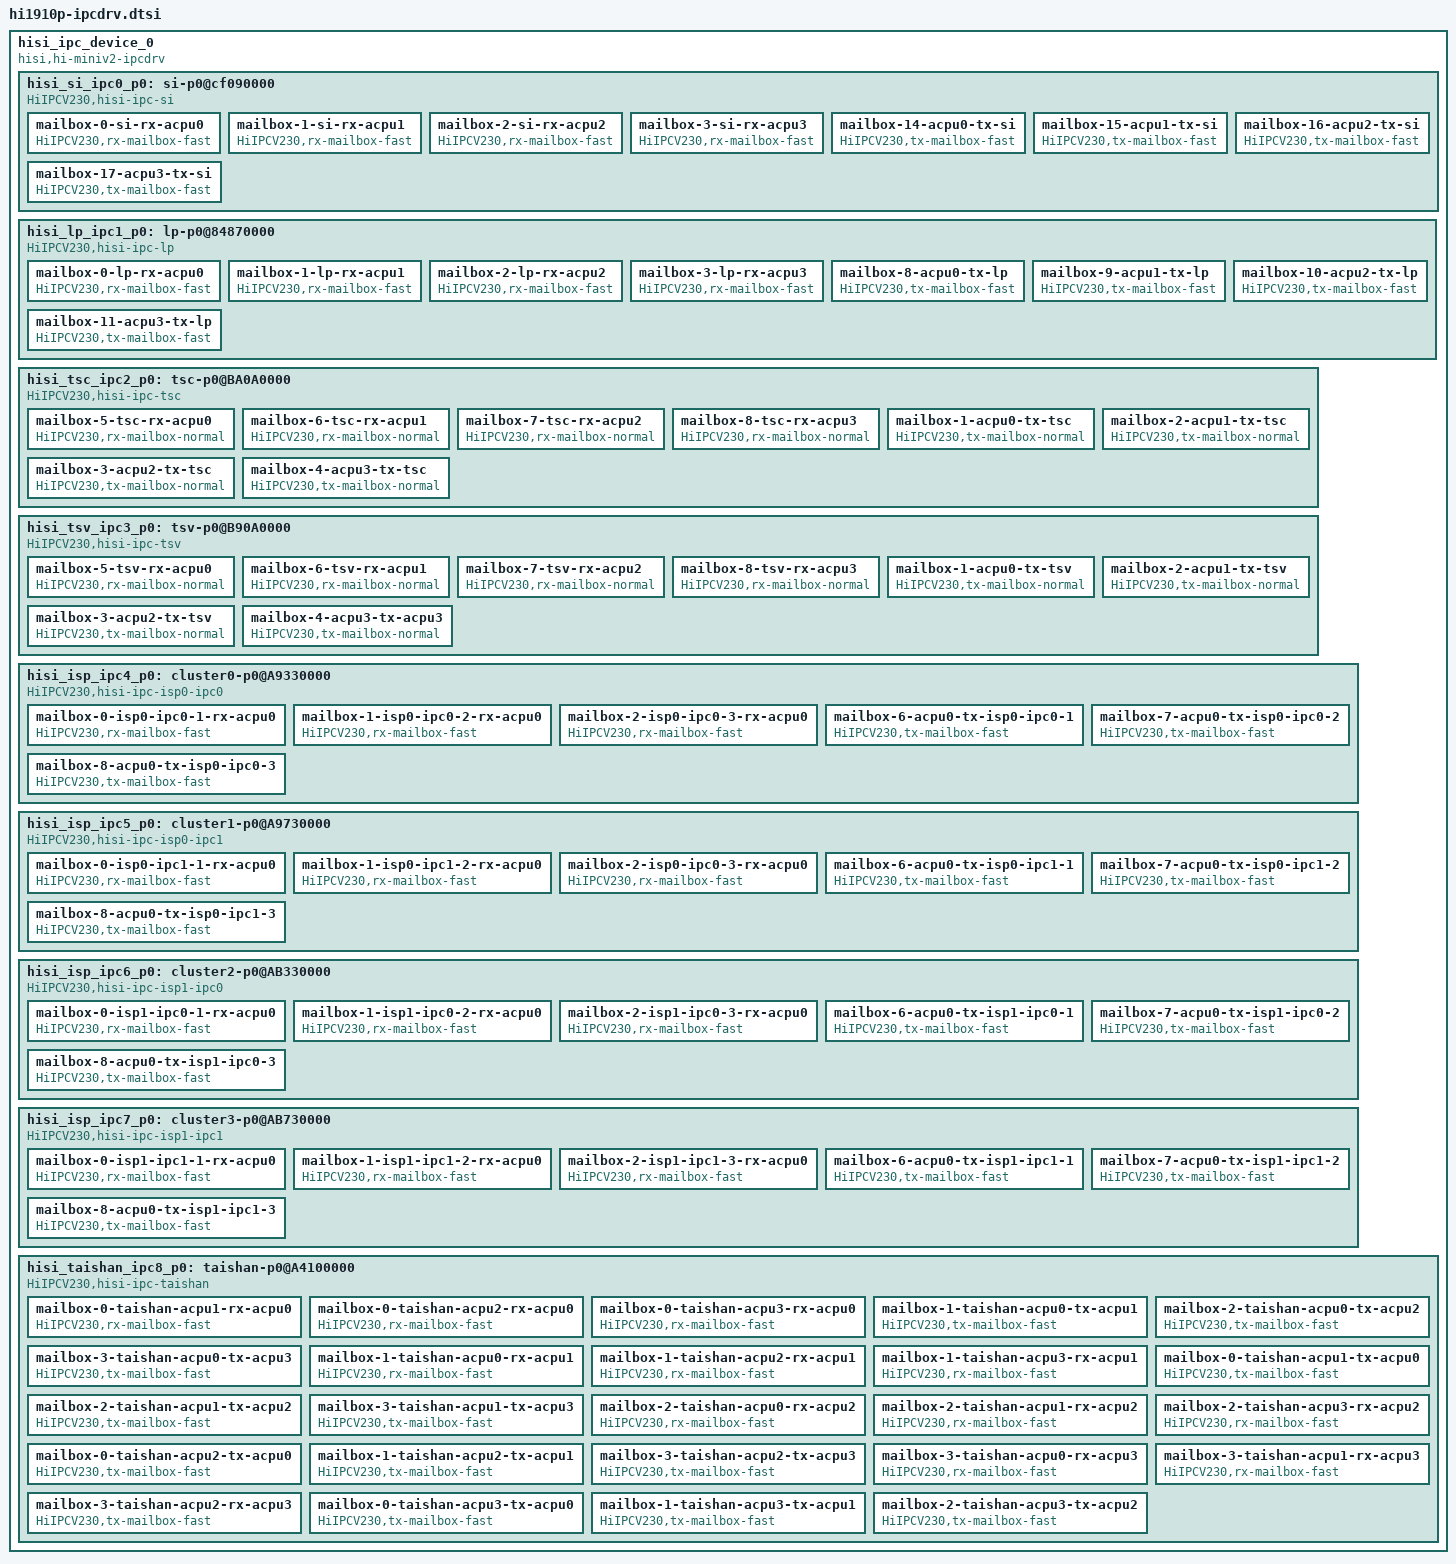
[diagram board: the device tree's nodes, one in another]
/*
 * Hisilicon Ltd. Hi3650 SoC
 *
 * Copyright (C) 2012-2014 Hisilicon Ltd.
 *
 * This program is free software; you can redistribute it and/or modify
 * it under the terms of the GNU General Public License version 2 as
 * publishhed by the Free Software Foundation.
 */
hisi_ipc_device_0 {
	#address-cells = <2>;
	#size-cells = <2>;

	compatible = "hisi,hi-miniv2-ipcdrv";
	mailboxes = <80>;
	ipc_id = <0>;
	ranges;

	/* ipc safe island quick unsafe mailbox */
	hisi_si_ipc0_p0: si-p0@cf090000 {
		#address-cells = <2>;
		#size-cells = <2>;
		compatible = "HiIPCV230,hisi-ipc-si";
		reg = <0x0 0xCF090000 0x0 0xB000>;
		interrupts = <0 194 4>, <0 261 4>, <0 265 4>, <0 281 4>;
			     /*ACPU0     ACPU1       ACPU2         ACPU3 */
		unlock_key = <0x1ACCE551>;
		capability = <8>;
		mailboxes = <8>;

		/*
		 * "func"
		 * <mbox_type, is_src_mbox, is_des_mbox>;
		 */

		/*si rx quick unsafe mbx channel*/
		mailbox-0-si-rx-acpu0 {
			compatible = "HiIPCV230,rx-mailbox-fast";
			func = <1 0 1>;
			interrupts = <0 193 4>;
			src_remote_processor = "MDC_IPC_SI_MBX0_RPID0_Q_RX_ACPU0";
			des_remote_processor = "HI1910P_AICPU0_MBX0";
			src_bit = <14>;
			des_bit = <0>;
			index = <0>;
		};

		mailbox-1-si-rx-acpu1 {
			compatible = "HiIPCV230,rx-mailbox-fast";
			func = <1 0 1>;
			interrupts = <0 260 4>;
			src_remote_processor = "MDC_IPC_SI_MBX1_RPID1_Q_RX_ACPU1";
			des_remote_processor = "HI1910P_AICPU1_MBX1";
			src_bit = <15>;
			des_bit = <1>;
			index = <1>;
		};

		mailbox-2-si-rx-acpu2 {
			compatible = "HiIPCV230,rx-mailbox-fast";
			func = <1 0 1>;
			interrupts = <0 264 4>;
			src_remote_processor = "MDC_IPC_SI_MBX2_RPID2_Q_RX_ACPU2";
			des_remote_processor = "HI1910P_AICPU2_MBX2";
			src_bit = <16>;
			des_bit = <2>;
			index = <2>;
		};

		mailbox-3-si-rx-acpu3 {
			compatible = "HiIPCV230,rx-mailbox-fast";
			func = <1 0 1>;
			interrupts = <0 280 4>;
			src_remote_processor = "MDC_IPC_SI_MBX3_RPID3_Q_RX_ACPU3";
			des_remote_processor = "HI1910P_AICPU3_MBX3";
			src_bit = <17>;
			des_bit = <3>;
			index = <3>;
		};

		/*si tx quick unsafe mbx channel*/
		mailbox-14-acpu0-tx-si {
			compatible = "HiIPCV230,tx-mailbox-fast";
			func = <1 1 0>;
			src_remote_processor = "HI1910P_AICPU0_MBX14";
			des_remote_processor = "MDC_IPC_SI_MBX14_RPID14_Q_TX_ACPU0";
			src_bit = <0>;
			des_bit = <14>;
			index = <14>;
		};

		mailbox-15-acpu1-tx-si {
			compatible = "HiIPCV230,tx-mailbox-fast";
			func = <1 1 0>;
			src_remote_processor = "HI1910P_AICPU1_MBX15";
			des_remote_processor = "MDC_IPC_SI_MBX15_RPID15_Q_TX_ACPU1";
			src_bit = <1>;
			des_bit = <15>;
			index = <15>;
		};

		mailbox-16-acpu2-tx-si {
			compatible = "HiIPCV230,tx-mailbox-fast";
			func = <1 1 0>;
			src_remote_processor = "HI1910P_AICPU2_MBX16";
			des_remote_processor = "MDC_IPC_SI_MBX16_RPID16_Q_TX_ACPU2";
			src_bit = <2>;
			des_bit = <16>;
			index = <16>;
		};

		mailbox-17-acpu3-tx-si {
			compatible = "HiIPCV230,tx-mailbox-fast";
			func = <1 1 0>;
			src_remote_processor = "HI1910P_AICPU3_MBX17";
			des_remote_processor = "MDC_IPC_SI_MBX17_RPID17_Q_TX_ACPU3";
			src_bit = <3>;
			des_bit = <17>;
			index = <17>;
		};

	};

	/* ipc LP quick unsafe mailbox */
	hisi_lp_ipc1_p0: lp-p0@84870000 {
		#address-cells = <2>;
		#size-cells = <2>;
		compatible = "HiIPCV230,hisi-ipc-lp";
		reg = <0x0 0x84870000 0x0 0xB000>;
		interrupts = <0 189 4>, <0 190 4>, <0 191 4>, <0 192 4>;
			     /*ACPU0     ACPU1       ACPU2         ACPU3 */

		unlock_key = <0x1ACCE551>;
		capability = <8>;
		mailboxes = <8>;

		/*
		 * "func"
		 * <mbox_type, is_src_mbox, is_des_mbox>;
		 */
		/*lp rx quick unsafe mbx channel*/
		mailbox-0-lp-rx-acpu0 {
			compatible = "HiIPCV230,rx-mailbox-fast";
			func = <1 0 1>;
			interrupts = <0 178 4>;
			src_remote_processor = "MDC_IPC_LP_MBX0_RPID0_Q_RX_ACPU0";
			des_remote_processor = "HI1910P_AICPU0_MBX0";
			src_bit = <4>;
			des_bit = <0>;
			index = <0>;
		};

		mailbox-1-lp-rx-acpu1 {
			compatible = "HiIPCV230,rx-mailbox-fast";
			func = <1 0 1>;
			interrupts = <0 179 4>;
			src_remote_processor = "MDC_IPC_LP_MBX1_RPID1_Q_RX_ACPU1";
			des_remote_processor = "HI1910P_AICPU1_MBX1";
			src_bit = <4>;
			des_bit = <1>;
			index = <1>;
		};

		mailbox-2-lp-rx-acpu2 {
			compatible = "HiIPCV230,rx-mailbox-fast";
			func = <1 0 1>;
			interrupts = <0 180 4>;
			src_remote_processor = "MDC_IPC_LP_MBX2_RPID2_Q_RX_ACPU2";
			des_remote_processor = "HI1910P_AICPU2_MBX2";
			src_bit = <4>;
			des_bit = <2>;
			index = <2>;
		};

		mailbox-3-lp-rx-acpu3 {
			compatible = "HiIPCV230,rx-mailbox-fast";
			func = <1 0 1>;
			interrupts = <0 181 4>;
			src_remote_processor = "MDC_IPC_LP_MBX3_RPID3_Q_RX_ACPU3";
			des_remote_processor = "HI1910P_AICPU3_MBX3";
			src_bit = <4>;
			des_bit = <3>;
			index = <3>;
		};

		/*lp tx quick unsafe mbx channel*/
		mailbox-8-acpu0-tx-lp {
			compatible = "HiIPCV230,tx-mailbox-fast";
			func = <1 1 0>;
			src_remote_processor = "HI1910P_AICPU0_MBX8";
			des_remote_processor = "MDC_IPC_LP_MBX8_RPID4_Q_TX_ACPU0";
			src_bit = <0>;
			des_bit = <4>;
			index = <8>;
		};

		mailbox-9-acpu1-tx-lp {
			compatible = "HiIPCV230,tx-mailbox-fast";
			func = <1 1 0>;
			src_remote_processor = "HI1910P_AICPU1_MBX9";
			des_remote_processor = "MDC_IPC_LP_MBX9_RPID4_Q_TX_ACPU1";
			src_bit = <1>;
			des_bit = <4>;
			index = <9>;
		};

		mailbox-10-acpu2-tx-lp {
			compatible = "HiIPCV230,tx-mailbox-fast";
			func = <1 1 0>;
			src_remote_processor = "HI1910P_AICPU2_MBX10";
			des_remote_processor = "MDC_IPC_LP_MBX10_RPID4_Q_TX_ACPU2";
			src_bit = <2>;
			des_bit = <4>;
			index = <10>;
		};

		mailbox-11-acpu3-tx-lp {
			compatible = "HiIPCV230,tx-mailbox-fast";
			func = <1 1 0>;
			src_remote_processor = "HI1910P_AICPU3_MBX11";
			des_remote_processor = "MDC_IPC_LP_MBX11_RPID4_Q_TX_ACPU3";
			src_bit = <3>;
			des_bit = <4>;
			index = <11>;
		};
	};

	/* ipc tsc normal unsafe mailbox */
	hisi_tsc_ipc2_p0: tsc-p0@BA0A0000 {
		#address-cells = <2>;
		#size-cells = <2>;
		compatible = "HiIPCV230,hisi-ipc-tsc";
		reg = <0x0 0xBA0A0000 0x0 0xB000>;
		interrupts = <0 224 4>, <0 225 4>, <0 226 4>, <0 227 4>;
			     /*ACPU0     ACPU1       ACPU2         ACPU3 */

		unlock_key = <0x1ACCE551>;
		capability = <8>;
		mailboxes = <8>;

		/*
		 * "func"
		 * <mbox_type, is_src_mbox, is_des_mbox>;
		 */
		/*tsc rx normal unsafe mbx channel*/
		mailbox-5-tsc-rx-acpu0 {
			compatible = "HiIPCV230,rx-mailbox-normal";
			func = <0 0 1>;
			interrupts = <0 224 4>;
			src_remote_processor = "MDC_IPC_TSC_MBX5_RPID4_RX_ACPU0";
			des_remote_processor = "HI1910P_AICPU0_MBX5";
			src_bit = <0>;
			des_bit = <4>;
			index = <5>;
		};

		mailbox-6-tsc-rx-acpu1 {
			compatible = "HiIPCV230,rx-mailbox-normal";
			func = <0 0 1>;
			interrupts = <0 225 4>;
			src_remote_processor = "MDC_IPC_TSC_MBX6_RPID5_RX_ACPU1";
			des_remote_processor = "HI1910P_AICPU1_MBX6";
			src_bit = <1>;
			des_bit = <5>;
			index = <6>;
		};

		mailbox-7-tsc-rx-acpu2 {
			compatible = "HiIPCV230,rx-mailbox-normal";
			func = <0 0 1>;
			interrupts = <0 226 4>;
			src_remote_processor = "MDC_IPC_TSC_MBX7_RPID6_RX_ACPU2";
			des_remote_processor = "HI1910P_AICPU2_MBX7";
			src_bit = <2>;
			des_bit = <6>;
			index = <7>;
		};

		mailbox-8-tsc-rx-acpu3 {
			compatible = "HiIPCV230,rx-mailbox-normal";
			func = <0 0 1>;
			interrupts = <0 227 4>;
			src_remote_processor = "MDC_IPC_TSC_MBX8_RPID7_RX_ACPU3";
			des_remote_processor = "HI1910P_AICPU3_MBX1";
			src_bit = <3>;
			des_bit = <7>;
			index = <8>;
		};

		/*tsc tx normal unsafe mbx channel*/
		mailbox-1-acpu0-tx-tsc {
			compatible = "HiIPCV230,tx-mailbox-normal";
			func = <0 1 0>;
			src_remote_processor = "HI1910P_AICPU0_MBX1";
			des_remote_processor = "MDC_IPC_TSC_MBX1_RPID0_TX_ACPU0";
			src_bit = <4>;
			des_bit = <0>;
			index = <1>;
		};

		mailbox-2-acpu1-tx-tsc {
			compatible = "HiIPCV230,tx-mailbox-normal";
			func = <0 1 0>;
			src_remote_processor = "HI1910P_AICPU1_MBX2";
			des_remote_processor = "MDC_IPC_TSC_MBX2_RPID1_TX_ACPU1";
			src_bit = <5>;
			des_bit = <1>;
			index = <2>;
		};

		mailbox-3-acpu2-tx-tsc {
			compatible = "HiIPCV230,tx-mailbox-normal";
			func = <0 1 0>;
			src_remote_processor = "HI1910P_AICPU2_MBX3";
			des_remote_processor = "MDC_IPC_TSC_MBX3_RPID2_TX_ACPU2";
			src_bit = <6>;
			des_bit = <2>;
			index = <3>;
		};

		mailbox-4-acpu3-tx-tsc {
			compatible = "HiIPCV230,tx-mailbox-normal";
			func = <0 1 0>;
			src_remote_processor = "HI1910P_AICPU3_MBX4";
			des_remote_processor = "MDC_IPC_TSC_MBX4_RPID3_TX_ACPU3";
			src_bit = <7>;
			des_bit = <3>;
			index = <4>;
		};
	};

	/* ipc tsv normal unsafe mailbox */
	hisi_tsv_ipc3_p0: tsv-p0@B90A0000 {
		#address-cells = <2>;
		#size-cells = <2>;
		compatible = "HiIPCV230,hisi-ipc-tsv";
		reg = <0x0 0xB90A0000 0x0 0xB000>;
		interrupts = <0 202 4>, <0 203 4>, <0 204 4>, <0 205 4>;
			     /*ACPU0     ACPU1       ACPU2         ACPU3 */

		unlock_key = <0x1ACCE551>;
		capability = <8>;
		mailboxes = <8>;
		/*
		 * "func"
		 * <mbox_type, is_src_mbox, is_des_mbox>;
		 */

		/*tsv rx normal unsafe mbx channel*/
		mailbox-5-tsv-rx-acpu0 {
			compatible = "HiIPCV230,rx-mailbox-normal";
			func = <0 0 1>;
			interrupts = <0 202 4>;
			src_remote_processor = "MDC_IPC_TSV_MBX5_RPID4_RX_ACPU0";
			des_remote_processor = "HI1910P_AICPU0_MBX5";
			src_bit = <0>;
			des_bit = <4>;
			index = <5>;
		};

		mailbox-6-tsv-rx-acpu1 {
			compatible = "HiIPCV230,rx-mailbox-normal";
			func = <0 0 1>;
			interrupts = <0 203 4>;
			src_remote_processor = "MDC_IPC_TSV_MBX6_RPID5_RX_ACPU1";
			des_remote_processor = "HI1910P_AICPU1_MBX6";
			src_bit = <1>;
			des_bit = <5>;
			index = <6>;
		};

		mailbox-7-tsv-rx-acpu2 {
			compatible = "HiIPCV230,rx-mailbox-normal";
			func = <0 0 1>;
			interrupts = <0 204 4>;
			src_remote_processor = "MDC_IPC_TSV_MBX7_RPID6_RX_ACPU2";
			des_remote_processor = "HI1910P_AICPU2_MBX7";
			src_bit = <2>;
			des_bit = <6>;
			index = <7>;
		};

		mailbox-8-tsv-rx-acpu3 {
			compatible = "HiIPCV230,rx-mailbox-normal";
			func = <0 0 1>;
			interrupts = <0 205 4>;
			src_remote_processor = "MDC_IPC_TSV_MBX8_RPID7_RX_ACPU3";
			des_remote_processor = "HI1910P_AICPU3_MBX1";
			src_bit = <3>;
			des_bit = <7>;
			index = <8>;
		};

		/*tsv tx normal unsafe mbx channel*/
		mailbox-1-acpu0-tx-tsv {
			compatible = "HiIPCV230,tx-mailbox-normal";
			func = <0 1 0>;
			src_remote_processor = "HI1910P_AICPU0_MBX1";
			des_remote_processor = "MDC_IPC_TSV_MBX1_RPID0_TX_ACPU0";
			src_bit = <4>;
			des_bit = <0>;
			index = <1>;
		};

		mailbox-2-acpu1-tx-tsv {
			compatible = "HiIPCV230,tx-mailbox-normal";
			func = <0 1 0>;
			src_remote_processor = "HI1910P_AICPU1_MBX2";
			des_remote_processor = "MDC_IPC_TSV_MBX2_RPID1_TX_ACPU1";
			src_bit = <5>;
			des_bit = <1>;
			index = <2>;
		};

		mailbox-3-acpu2-tx-tsv {
			compatible = "HiIPCV230,tx-mailbox-normal";
			func = <0 1 0>;
			src_remote_processor = "HI1910P_AICPU2_MBX3";
			des_remote_processor = "MDC_IPC_TSV_MBX3_RPID2_TX_ACPU2";
			src_bit = <6>;
			des_bit = <2>;
			index = <3>;
		};

		mailbox-4-acpu3-tx-acpu3 {
			compatible = "HiIPCV230,tx-mailbox-normal";
			func = <0 1 0>;
			src_remote_processor = "HI1910P_AICPU3_MBX4";
			des_remote_processor = "MDC_IPC_TSV_MBX4_RPID3_TX_ACPU3";
			src_bit = <7>;
			des_bit = <3>;
			index = <4>;
		};
	};

	/* ISP IPC Mailbox
	 * 1. Only use Unsafe Quick channel
	 * 2. Use common channels' interrupts as ack
	 * 3. Three tx channels but one ack interrupt
	 * 4. 4 ipc devices, 24 channels, 16 interrupts
	 */
	/* ISP0_IPC0 */
	hisi_isp_ipc4_p0: cluster0-p0@A9330000 {
		#address-cells = <2>;
		#sizec-cells = <2>;
		compatible = "HiIPCV230,hisi-ipc-isp0-ipc0";
		reg = <0x0 0xA9330000 0x0 0xB000>;
		/* Three channels but one ack, write 4 for align */
		interrupts = <0 278 4>, <0 278 4>, <0 278 4>, <0 278 4>;
		unlock_key = <0x1ACCE551>;
		capability = <8>;
		mailboxes = <6>;

		/* RX */
		mailbox-0-isp0-ipc0-1-rx-acpu0 {
			compatible = "HiIPCV230,rx-mailbox-fast";
			func = <1 0 1>;
			interrupts = <0 272 4>;
			irq_affinity = <10>;
			src_remote_processor = "IPC_ISP0_IPC0_MBX0_RPID0_Q_RX_ACPU0";
			des_remote_processor = "RX_DES_ACPU0_ID4_MBX0";
			src_bit = <1>;
			des_bit = <0>;
			index = <0>;
		};

		mailbox-1-isp0-ipc0-2-rx-acpu0 {
			compatible = "HiIPCV230,rx-mailbox-fast";
			func = <1 0 1>;
			interrupts = <0 273 4>;
			irq_affinity = <10>;
			src_remote_processor = "IPC_ISP0_IPC0_MBX1_RPID0_Q_RX_ACPU0";
			des_remote_processor = "RX_DES_ACPU0_ID4_MBX1";
			src_bit = <2>;
			des_bit = <0>;
			index = <1>;
		};

		mailbox-2-isp0-ipc0-3-rx-acpu0 {
			compatible = "HiIPCV230,rx-mailbox-fast";
			func = <1 0 1>;
			interrupts = <0 274 4>;
			irq_affinity = <10>;
			src_remote_processor = "IPC_ISP0_IPC0_MBX2_RPID0_Q_RX_ACPU0";
			des_remote_processor = "RX_DES_ACPU0_ID4_MBX2";
			src_bit = <3>;
			des_bit = <0>;
			index = <2>;
		};

		/* TX */
		mailbox-6-acpu0-tx-isp0-ipc0-1 {
			compatible = "HiIPCV230,tx-mailbox-fast";
			func = <1 1 0>;
			src_remote_processor = "TX_SRC_ISP0_IPC0_ID4_MBX6";
			des_remote_processor = "IPC_ISP0_IPC0_MBX6_RPID0_Q_TX_ACPU0";
			src_bit = <0>;
			des_bit = <1>;
			index = <6>;
		};

		mailbox-7-acpu0-tx-isp0-ipc0-2 {
			compatible = "HiIPCV230,tx-mailbox-fast";
			func = <1 1 0>;
			src_remote_processor = "TX_SRC_ISP0_IPC0_ID4_MBX7";
			des_remote_processor = "IPC_ISP0_IPC0_MBX7_RPID0_Q_TX_ACPU0";
			src_bit = <0>;
			des_bit = <2>;
			index = <7>;
		};

		mailbox-8-acpu0-tx-isp0-ipc0-3 {
			compatible = "HiIPCV230,tx-mailbox-fast";
			func = <1 1 0>;
			src_remote_processor = "TX_SRC_ISP0_IPC0_ID4_MBX8";
			des_remote_processor = "IPC_ISP0_IPC0_MBX8_RPID0_Q_TX_ACPU0";
			src_bit = <0>;
			des_bit = <3>;
			index = <8>;
		};
	};
	/* ISP0-IPC1 */
	hisi_isp_ipc5_p0: cluster1-p0@A9730000 {
		#address-cells = <2>;
		#size-cells = <2>;
		compatible = "HiIPCV230,hisi-ipc-isp0-ipc1";
		reg = <0x0 0xA9730000 0x0 0xB000>;
		interrupts = <0 279 4>, <0 279 4>, <0 279 4>, <0 279 4>;
		unlock_key = <0x1ACCE551>;
		capability = <8>;
		mailboxes = <6>;

		/* RX */
		mailbox-0-isp0-ipc1-1-rx-acpu0 {
			compatible = "HiIPCV230,rx-mailbox-fast";
			func = <1 0 1>;
			interrupts = <0 275 4>;
			irq_affinity = <10>;
			src_remote_processor = "IPC_ISP0_IPC1_MBX0_RPID0_Q_RX_ACPU0";
			des_remote_processor = "RX_DES_ISP0_IPC1_ID5_MBX0";
			src_bit = <1>;
			des_bit = <0>;
			index = <0>;
		};

		mailbox-1-isp0-ipc1-2-rx-acpu0 {
			compatible = "HiIPCV230,rx-mailbox-fast";
			func = <1 0 1>;
			interrupts = <0 276 4>;
			irq_affinity = <10>;
			src_remote_processor = "IPC_ISP0_IPC1_MBX1_RPID0_Q_RX_ACPU0";
			des_remote_processor = "RX_DES_ISP0_IPC1_ID5_MBX1";
			src_bit = <2>;
			des_bit = <0>;
			index = <1>;
		};

		mailbox-2-isp0-ipc0-3-rx-acpu0 {
			compatible = "HiIPCV230,rx-mailbox-fast";
			func = <1 0 1>;
			interrupts = <0 277 4>;
			irq_affinity = <10>;
			src_remote_processor = "IPC_ISP0_IPC1_MBX2_RPID0_Q_RX_ACPU0";
			des_remote_processor = "RX_DES_ISP0_IPC1_ID5_MBX2";
			src_bit = <3>;
			des_bit = <0>;
			index = <2>;
		};

		/* TX */
		mailbox-6-acpu0-tx-isp0-ipc1-1 {
			compatible = "HiIPCV230,tx-mailbox-fast";
			func = <1 1 0>;
			src_remote_processor = "TX_SRC_ISP0_IPC1_ID5_MBX6";
			des_remote_processor = "IPC_ISP0_IPC1_MBX6_RPID0_Q_TX_ACPU0";
			src_bit = <0>;
			des_bit = <1>;
			index = <6>;
		};

		mailbox-7-acpu0-tx-isp0-ipc1-2 {
			compatible = "HiIPCV230,tx-mailbox-fast";
			func = <1 1 0>;
			src_remote_processor = "TX_SRC_ISP0_IPC1_ID5_MBX7";
			des_remote_processor = "IPC_ISP0_IPC1_MBX7_RPID0_Q_TX_ACPU0";
			src_bit = <0>;
			des_bit = <2>;
			index = <7>;
		};

		mailbox-8-acpu0-tx-isp0-ipc1-3 {
			compatible = "HiIPCV230,tx-mailbox-fast";
			func = <1 1 0>;
			src_remote_processor = "TX_SRC_ISP0_IPC1_ID5_MBX8";
			des_remote_processor = "IPC_ISP0_IPC1_MBX8_RPID0_Q_TX_ACPU0";
			src_bit = <0>;
			des_bit = <3>;
			index = <8>;
		};
	};

	/* ISP1-IPC0 */
	hisi_isp_ipc6_p0: cluster2-p0@AB330000 {
		#address-cells = <2>;
		#size-cells = <2>;
		compatible = "HiIPCV230,hisi-ipc-isp1-ipc0";
		reg = <0x0 0xAB330000 0x0 0xB000>;
		interrupts = <0 288 4>, <0 288 4>, <0 288 4>, <0 288 4>;
		unlock_key = <0x1ACCE551>;
		capability = <8>;
		mailboxes = <6>;

		/* RX */
		mailbox-0-isp1-ipc0-1-rx-acpu0 {
			compatible = "HiIPCV230,rx-mailbox-fast";
			func = <1 0 1>;
			interrupts = <0 299 4>;
			irq_affinity = <11>;
			src_remote_processor = "IPC_ISP1_IPC0_MBX0_RPID0_Q_RX_ACPU0";
			des_remote_processor = "RX_DES_ISP1_IPC0_ID6_MBX0";
			src_bit = <1>;
			des_bit = <0>;
			index = <0>;
		};

		mailbox-1-isp1-ipc0-2-rx-acpu0 {
			compatible = "HiIPCV230,rx-mailbox-fast";
			func = <1 0 1>;
			interrupts = <0 300 4>;
			irq_affinity = <11>;
			src_remote_processor = "IPC_ISP1_IPC0_MBX1_RPID0_Q_RX_ACPU0";
			des_remote_processor = "RX_DES_ISP1_IPC0_ID6_MBX1";
			src_bit = <2>;
			des_bit = <0>;
			index = <1>;
		};

		mailbox-2-isp1-ipc0-3-rx-acpu0 {
			compatible = "HiIPCV230,rx-mailbox-fast";
			func = <1 0 1>;
			interrupts = <0 301 4>;
			irq_affinity = <11>;
			src_remote_processor = "IPC_ISP1_IPC0_MBX2_RPID0_Q_RX_ACPU0";
			des_remote_processor = "RX_DES_ISP1_IPC0_ID6_MBX2";
			src_bit = <3>;
			des_bit = <0>;
			index = <2>;
		};

		/* TX */
		mailbox-6-acpu0-tx-isp1-ipc0-1 {
			compatible = "HiIPCV230,tx-mailbox-fast";
			func = <1 1 0>;
			src_remote_processor = "TX_SRC_ISP1_IPC0_ID6_MBX6";
			des_remote_processor = "IPC_ISP1_IPC0_MBX6_RPID0_Q_TX_ACPU0";
			src_bit = <0>;
			des_bit = <1>;
			index = <6>;
		};

		mailbox-7-acpu0-tx-isp1-ipc0-2 {
			compatible = "HiIPCV230,tx-mailbox-fast";
			func = <1 1 0>;
			src_remote_processor = "TX_SRC_ISP1_IPC0_ID6_MBX7";
			des_remote_processor = "IPC_ISP1_IPC0_MBX7_RPID0_Q_TX_ACPU0";
			src_bit = <0>;
			des_bit = <2>;
			index = <7>;
		};

		mailbox-8-acpu0-tx-isp1-ipc0-3 {
			compatible = "HiIPCV230,tx-mailbox-fast";
			func = <1 1 0>;
			src_remote_processor = "TX_SRC_ISP1_IPC0_ID6_MBX8";
			des_remote_processor = "IPC_ISP1_IPC0_MBX8_RPID0_Q_TX_ACPU0";
			src_bit = <0>;
			des_bit = <3>;
			index = <8>;
		};
	};

	/* ISP1-IPC1 */
	hisi_isp_ipc7_p0: cluster3-p0@AB730000 {
		#address-cells = <2>;
		#size-cells = <2>;
		compatible = "HiIPCV230,hisi-ipc-isp1-ipc1";
		reg = <0x0 0xAB730000 0x0 0xB000>;
		interrupts = <0 289 4>, <0 289 4>, <0 289 4>, <0 289 4>;
		unlock_key = <0x1ACCE551>;
		capability = <8>;
		mailboxes = <6>;

		/* RX */
		mailbox-0-isp1-ipc1-1-rx-acpu0 {
			compatible = "HiIPCV230,rx-mailbox-fast";
			func = <1 0 1>;
			interrupts = <0 302 4>;
			irq_affinity = <11>;
			src_remote_processor = "IPC_ISP1_IPC1_MBX0_RPID0_Q_RX_ACPU0";
			des_remote_processor = "RX_DES_ISP1_IPC1_ID7_MBX0";
			src_bit = <1>;
			des_bit = <0>;
			index = <0>;
		};

		mailbox-1-isp1-ipc1-2-rx-acpu0 {
			compatible = "HiIPCV230,rx-mailbox-fast";
			func = <1 0 1>;
			interrupts = <0 303 4>;
			irq_affinity = <11>;
			src_remote_processor = "IPC_ISP1_IPC1_MBX1_RPID0_Q_RX_ACPU0";
			des_remote_processor = "RX_DES_ISP1_IPC1_ID7_MBX1";
			src_bit = <2>;
			des_bit = <0>;
			index = <1>;
		};

		mailbox-2-isp1-ipc1-3-rx-acpu0 {
			compatible = "HiIPCV230,rx-mailbox-fast";
			func = <1 0 1>;
			interrupts = <0 304 4>;
			irq_affinity = <11>;
			src_remote_processor = "IPC_ISP1_IPC1_MBX2_RPID0_Q_RX_ACPU0";
			des_remote_processor = "RX_DES_ISP1_IPC1_ID7_MBX2";
			src_bit = <3>;
			des_bit = <0>;
			index = <2>;
		};

		/* TX */
		mailbox-6-acpu0-tx-isp1-ipc1-1 {
			compatible = "HiIPCV230,tx-mailbox-fast";
			func = <1 1 0>;
			src_remote_processor = "TX_SRC_ISP1_IPC1_ID7_MBX6";
			des_remote_processor = "IPC_ISP1_IPC1_MBX6_RPID0_Q_TX_ACPU0";
			src_bit = <0>;
			des_bit = <1>;
			index = <6>;
		};

		mailbox-7-acpu0-tx-isp1-ipc1-2 {
			compatible = "HiIPCV230,tx-mailbox-fast";
			func = <1 1 0>;
			src_remote_processor = "TX_SRC_ISP1_IPC1_ID7_MBX7";
			des_remote_processor = "IPC_ISP1_IPC1_MBX7_RPID0_Q_TX_ACPU0";
			src_bit = <0>;
			des_bit = <2>;
			index = <7>;
		};

		mailbox-8-acpu0-tx-isp1-ipc1-3 {
			compatible = "HiIPCV230,tx-mailbox-fast";
			func = <1 1 0>;
			src_remote_processor = "TX_SRC_ISP1_IPC1_ID7_MBX8";
			des_remote_processor = "IPC_ISP1_IPC1_MBX8_RPID0_Q_TX_ACPU0";
			src_bit = <0>;
			des_bit = <3>;
			index = <8>;
		};
	};

	/* IPC For TaiShan */
	hisi_taishan_ipc8_p0: taishan-p0@A4100000 {
		#address-cells = <2>;
		#size-cells = <2>;
		compatible = "HiIPCV230,hisi-ipc-taishan";
		reg = <0x0 0xA4100000 0x0 0xB000>;
		interrupts = <0 130 4>, <0 131 4>, <0 132 4>, <0 133 4>;
		unlock_key = <0x1ACCE551>;
		capability = <8>;
		mailboxes = <24>;

		/* ACPU 0 */
		/* RX */
		mailbox-0-taishan-acpu1-rx-acpu0 {
			compatible = "HiIPCV230,rx-mailbox-fast";
			func = <1 0 1>;
			interrupts = <0 126 4>;
			src_remote_processor = "IPC_TAISHAN_MBX0_RPID1_RX_ACPU0";
			des_remote_processor = "IPC_TAISHAN_MBX0_ACPU1";
			src_bit = <1>;
			des_bit = <0>;
			index = <0>;
		};
		mailbox-0-taishan-acpu2-rx-acpu0 {
			compatible = "HiIPCV230,rx-mailbox-fast";
			func = <1 0 1>;
			interrupts = <0 126 4>;
			src_remote_processor = "IPC_TAISHAN_MBX0_RPID2_RX_ACPU0";
			des_remote_processor = "IPC_TAISHAN_MBX0_ACPU1";
			src_bit = <2>;
			des_bit = <0>;
			index = <0>;
		};
		mailbox-0-taishan-acpu3-rx-acpu0 {
			compatible = "HiIPCV230,rx-mailbox-fast";
			func = <1 0 1>;
			interrupts = <0 126 4>;
			src_remote_processor = "IPC_TAISHAN_MBX0_RPID3_RX_ACPU0";
			des_remote_processor = "IPC_TAISHAN_MBX0_ACPU1";
			src_bit = <3>;
			des_bit = <0>;
			index = <0>;
		};
		/* TX */
		mailbox-1-taishan-acpu0-tx-acpu1 {
			compatible = "HiIPCV230,tx-mailbox-fast";
			func = <1 1 0>;
			src_remote_processor = "IPC_TAISHAN_MBX1_ACPU0";
			des_remote_processor = "IPC_TAISHAN_MBX1_ACPU0_TX_RPID1";
			src_bit = <0>;
			des_bit = <1>;
			index = <1>;
		};
		mailbox-2-taishan-acpu0-tx-acpu2 {
			compatible = "HiIPCV230,tx-mailbox-fast";
			func = <1 1 0>;
			src_remote_processor = "IPC_TAISHAN_MBX2_ACPU0";
			des_remote_processor = "IPC_TAISHAN_MBX2_ACPU0_TX_RPID2";
			src_bit = <0>;
			des_bit = <2>;
			index = <2>;
		};
		mailbox-3-taishan-acpu0-tx-acpu3 {
			compatible = "HiIPCV230,tx-mailbox-fast";
			func = <1 1 0>;
			src_remote_processor = "IPC_TAISHAN_MBX3_ACPU0";
			des_remote_processor = "IPC_TAISHAN_MBX3_ACPU0_TX_RPID3";
			src_bit = <0>;
			des_bit = <3>;
			index = <3>;
		};

		/* ACPU1 */
		/* RX */
		mailbox-1-taishan-acpu0-rx-acpu1 {
			compatible = "HiIPCV230,rx-mailbox-fast";
			func = <1 0 1>;
			interrupts = <0 127 4>;
			src_remote_processor = "IPC_TAISHAN_MBX1_RPID0_RX_ACPU1";
			des_remote_processor = "IPC_TAISHAN_MBX1_ACPU1";
			src_bit = <0>;
			des_bit = <1>;
			index = <1>;
		};
		mailbox-1-taishan-acpu2-rx-acpu1 {
			compatible = "HiIPCV230,rx-mailbox-fast";
			func = <1 0 1>;
			interrupts = <0 127 4>;
			src_remote_processor = "IPC_TAISHAN_MBX1_RPID2_RX_ACPU1";
			des_remote_processor = "IPC_TAISHAN_MBX1_ACPU1";
			src_bit = <2>;
			des_bit = <1>;
			index = <1>;
		};
		mailbox-1-taishan-acpu3-rx-acpu1 {
			compatible = "HiIPCV230,rx-mailbox-fast";
			func = <1 0 1>;
			interrupts = <0 127 4>;
			src_remote_processor = "IPC_TAISHAN_MBX1_RPID3_RX_ACPU1";
			des_remote_processor = "IPC_TAISHAN_MBX1_ACPU1";
			src_bit = <3>;
			des_bit = <1>;
			index = <1>;
		};
		/* TX */
		mailbox-0-taishan-acpu1-tx-acpu0 {
			compatible = "HiIPCV230,tx-mailbox-fast";
			func = <1 1 0>;
			src_remote_processor = "IPC_TAISHAN_MBX0_ACPU1";
			des_remote_processor = "IPC_TAISHAN_MBX0_ACPU1_TX_RPID0";
			src_bit = <1>;
			des_bit = <0>;
			index = <0>;
		};
		mailbox-2-taishan-acpu1-tx-acpu2 {
			compatible = "HiIPCV230,tx-mailbox-fast";
			func = <1 1 0>;
			src_remote_processor = "IPC_TAISHAN_MBX2_ACPU1";
			des_remote_processor = "IPC_TAISHAN_MBX2_ACPU1_TX_RPID2";
			src_bit = <1>;
			des_bit = <2>;
			index = <2>;
		};
		mailbox-3-taishan-acpu1-tx-acpu3 {
			compatible = "HiIPCV230,tx-mailbox-fast";
			func = <1 1 0>;
			src_remote_processor = "IPC_TAISHAN_MBX3_ACPU1";
			des_remote_processor = "IPC_TAISHAN_MBX3_ACPU1_TX_RPID3";
			src_bit = <1>;
			des_bit = <3>;
			index = <3>;
		};

		/* ACPU2 */
		/* RX */
		mailbox-2-taishan-acpu0-rx-acpu2 {
			compatible = "HiIPCV230,rx-mailbox-fast";
			func = <1 0 1>;
			interrupts = <0 128 4>;
			src_remote_processor = "IPC_TAISHAN_MBX2_RPID0_RX_ACPU2";
			des_remote_processor = "IPC_TAISHAN_MBX2_ACPU2";
			src_bit = <0>;
			des_bit = <2>;
			index = <2>;
		};
		mailbox-2-taishan-acpu1-rx-acpu2 {
			compatible = "HiIPCV230,rx-mailbox-fast";
			func = <1 0 1>;
			interrupts = <0 128 4>;
			src_remote_processor = "IPC_TAISHAN_MBX2_RPID1_RX_ACPU2";
			des_remote_processor = "IPC_TAISHAN_MBX2_ACPU2";
			src_bit = <1>;
			des_bit = <2>;
			index = <2>;
		};
		mailbox-2-taishan-acpu3-rx-acpu2 {
			compatible = "HiIPCV230,rx-mailbox-fast";
			func = <1 0 1>;
			interrupts = <0 128 4>;
			src_remote_processor = "IPC_TAISHAN_MBX2_RPID3_RX_ACPU2";
			des_remote_processor = "IPC_TAISHAN_MBX2_ACPU2";
			src_bit = <3>;
			des_bit = <2>;
			index = <2>;
		};
		/* TX */
		mailbox-0-taishan-acpu2-tx-acpu0 {
			compatible = "HiIPCV230,tx-mailbox-fast";
			func = <1 1 0>;
			src_remote_processor = "IPC_TAISHAN_MBX0_ACPU2";
			des_remote_processor = "IPC_TAISHAN_MBX0_ACPU2_TX_RPID0";
			src_bit = <2>;
			des_bit = <0>;
			index = <0>;
		};
		mailbox-1-taishan-acpu2-tx-acpu1 {
			compatible = "HiIPCV230,tx-mailbox-fast";
			func = <1 1 0>;
			src_remote_processor = "IPC_TAISHAN_MBX1_ACPU2";
			des_remote_processor = "IPC_TAISHAN_MBX1_ACPU2_TX_RPID1";
			src_bit = <2>;
			des_bit = <1>;
			index = <1>;
		};
		mailbox-3-taishan-acpu2-tx-acpu3 {
			compatible = "HiIPCV230,tx-mailbox-fast";
			func = <1 1 0>;
			src_remote_processor = "IPC_TAISHAN_MBX3_ACPU2";
			des_remote_processor = "IPC_TAISHAN_MBX3_ACPU2_TX_RPID3";
			src_bit = <2>;
			des_bit = <3>;
			index = <3>;
		};

		/* ACPU3 */
		/* RX */
		mailbox-3-taishan-acpu0-rx-acpu3 {
			compatible = "HiIPCV230,rx-mailbox-fast";
			func = <1 0 1>;
			interrupts = <0 129 4>;
			src_remote_processor = "IPC_TAISHAN_MBX3_RPID0_RX_ACPU3";
			des_remote_processor = "IPC_TAISHAN_MBX3_ACPU3";
			src_bit = <0>;
			des_bit = <3>;
			index = <3>;
		};
		mailbox-3-taishan-acpu1-rx-acpu3 {
			compatible = "HiIPCV230,rx-mailbox-fast";
			func = <1 0 1>;
			interrupts = <0 129 4>;
			src_remote_processor = "IPC_TAISHAN_MBX3_RPID1_RX_ACPU3";
			des_remote_processor = "IPC_TAISHAN_MBX3_ACPU3";
			src_bit = <1>;
			des_bit = <3>;
			index = <3>;
		};
		mailbox-3-taishan-acpu2-rx-acpu3 {
			compatible = "HiIPCV230,tx-mailbox-fast";
			func = <1 0 1>;
			interrupts = <0 129 4>;
			src_remote_processor = "IPC_TAISHAN_MBX3_RPID2_RX_ACPU3";
			des_remote_processor = "IPC_TAISHAN_MBX3_ACPU3";
			src_bit = <2>;
			des_bit = <3>;
			index = <3>;
		};
		/* TX */
		mailbox-0-taishan-acpu3-tx-acpu0 {
			compatible = "HiIPCV230,tx-mailbox-fast";
			func = <1 1 0>;
			src_remote_processor = "IPC_TAISHAN_MBX0_ACPU3";
			des_remote_processor = "IPC_TAISHAN_MBX0_ACPU3_TX_RPID0";
			src_bit = <3>;
			des_bit = <0>;
			index = <0>;
		};
		mailbox-1-taishan-acpu3-tx-acpu1 {
			compatible = "HiIPCV230,tx-mailbox-fast";
			func = <1 1 0>;
			src_remote_processor = "IPC_TAISHAN_MBX1_ACPU3";
			des_remote_processor = "IPC_TAISHAN_MBX1_ACPU3_TX_RPID1";
			src_bit = <3>;
			des_bit = <1>;
			index = <1>;
		};
		mailbox-2-taishan-acpu3-tx-acpu2 {
			compatible = "HiIPCV230,tx-mailbox-fast";
			func = <1 1 0>;
			src_remote_processor = "IPC_TAISHAN_MBX2_ACPU3";
			des_remote_processor = "IPC_TAISHAN_MBX2_ACPU3_TX_RPID2";
			src_bit = <3>;
			des_bit = <2>;
			index = <2>;
		};
	};
};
